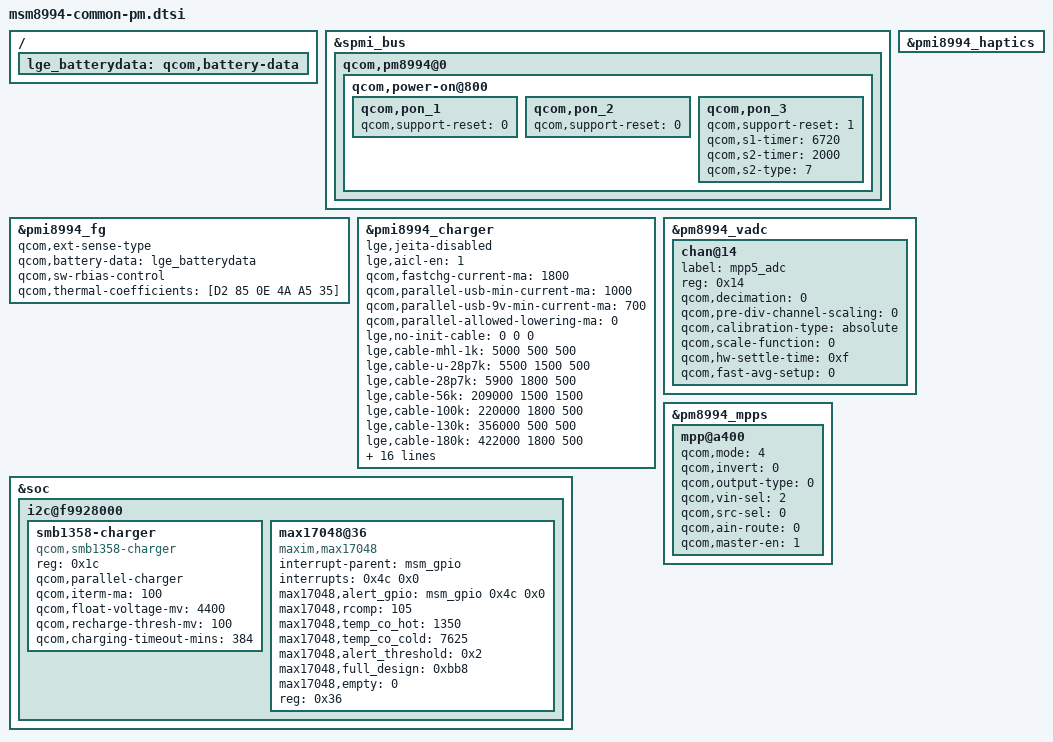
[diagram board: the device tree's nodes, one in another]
&spmi_bus {
	qcom,pm8994@0 {
		qcom,power-on@800 {
			qcom,pon_1 { /* KPD_PWR_N reset */
				status = "ok";
				qcom,support-reset = <0>;
			};

			qcom,pon_2 { /* RESIN_N reset   */
				status = "ok";
				qcom,support-reset = <0>;
			};

			qcom,pon_3 { /* KPD_PWR_N AND RESIN_N reset */
				status = "ok";
				qcom,support-reset = <1>;
				qcom,s1-timer = <6720>;
				qcom,s2-timer = <2000>;
				qcom,s2-type = <7>;
			};
		};
	};
};

/{
	lge_batterydata: qcom,battery-data {
		#include "batterydata-lge-blt16-4v35-3000mah.dtsi"
	};
};

&pmi8994_fg {
	status = "ok";

	qcom,ext-sense-type;
	qcom,battery-data = <&lge_batterydata>;
	qcom,sw-rbias-control;
	qcom,thermal-coefficients = [D2 85 0E 4A A5 35];
};

&pmi8994_charger {
	status = "ok";

	lge,jeita-disabled;
	lge,aicl-en = <1>;
	qcom,fastchg-current-ma = <1800>;
	qcom,parallel-usb-min-current-ma = <1000>;
	qcom,parallel-usb-9v-min-current-ma = <700>;
	qcom,parallel-allowed-lowering-ma = <0>;

	lge,no-init-cable = <0 0 0>;
	lge,cable-mhl-1k = <5000 500 500>;
	lge,cable-u-28p7k = <5500 1500 500>;
	lge,cable-28p7k = <5900 1800 500>;
	lge,cable-56k = <209000 1500 1500>;
	lge,cable-100k = <220000 1800 500>;
	lge,cable-130k = <356000 500 500>;
	lge,cable-180k = <422000 1800 500>;
	lge,cable-200k = <433000 1800 500>;
	lge,cable-220k = <509000 1800 500>;
	lge,cable-270k = <586000 1800 500>;
	lge,cable-330k = <763000 1800 500>;
	lge,cable-620k = <971000 1800 500>;
	lge,cable-910k = <1172000 1500 1500>;
	lge,cable-none = <1900000 1800  500>;
	qcom,iterm-ma = <100>;
	qcom,float-voltage-mv = <4350>;
	qcom,resume-delta-mv = <200>;
	qcom,charge-unknown-battery;
	qcom,charging-timeout-mins = <768>;
	qcom,chg-vadc = <&pmi8994_vadc>;
	qcom,smb-vadc = <&pm8994_vadc>;
	qcom,dc-psy-type;
	qcom,bmd-pin-src="bpd_none";
};

&soc {
	i2c@f9928000 { /* BLSP1 QUP6 */
		status = "ok";
		smb1358-charger{
			status = "ok";
			compatible = "qcom,smb1358-charger";
			reg = <0x1c>;
			qcom,parallel-charger;
			qcom,iterm-ma = <100>;
			qcom,float-voltage-mv = <4400>;
			qcom,recharge-thresh-mv = <100>;
			qcom,charging-timeout-mins = <384>;
		};

		max17048@36 {
			status = "ok";
			compatible = "maxim,max17048";
			interrupt-parent = <&msm_gpio>;
			interrupts = <0x4c 0x0>;
			max17048,alert_gpio = <&msm_gpio 0x4c 0x0>;
			max17048,rcomp = <105>;
			max17048,temp_co_hot = <1350>;
			max17048,temp_co_cold = <7625>;
			max17048,alert_threshold = <0x2>;
			max17048,full_design = <0xbb8>;
			max17048,empty = <0>;
			reg = <0x36>;
		};
	};
};

&pmi8994_haptics {
	status = "okay";
};

&pm8994_vadc {
	chan@14{
		status = "ok";
		label ="mpp5_adc";
		reg = <0x14>;
		qcom,decimation = <0>;
		qcom,pre-div-channel-scaling = <0>;
		qcom,calibration-type = "absolute";
		qcom,scale-function = <0>;
		qcom,hw-settle-time = <0xf>;
		qcom,fast-avg-setup = <0>;
	};
};

&pm8994_mpps {
	mpp@a400 { /* MPP 5 */
		status = "ok";
		qcom,mode = <4>;
		qcom,invert = <0>;
		qcom,output-type = <0>;         /* CMOS logic */
		qcom,vin-sel = <2>;             /* S4 1.8V */
		qcom,src-sel = <0>;             /* Constant */
		qcom,ain-route = <0>;           /* Channel */
		qcom,master-en = <1>;           /* Enable GPIO */
	};

};
